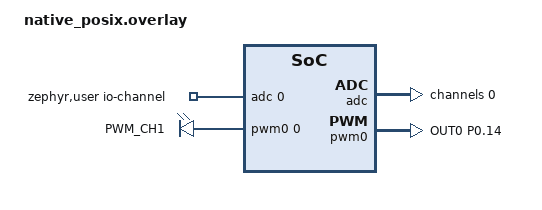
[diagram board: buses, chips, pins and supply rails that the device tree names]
/ {
        zephyr,user {
            io-channels = <&adc 0>;
        };
        aliases {
        // add your aliases here; examples:
        heartbeat = &led0;  // this corresponds to LED1 on the board
        blinker = &led1;
        // buzzer = &led2;
        error = &led3;
        readbutton = &button0;  // this corresponds to SW1 on the board
        // samplingbutton = &button1;
        sleepbutton = &button2;
        resetbutton = &button3;
        vadc = &vadc;
        pwm1 = &pwmch1;
        };
        pwm {
            compatible = "pwm-leds";
            pwmch1: pwm_1 {
                pwms = < &pwm0 0 PWM_MSEC(1) PWM_POLARITY_INVERTED>;  // 0 - channel
                label = "PWM_CH1";
            };
        };
};

&adc {
    #address-cells = <1>;
    #size-cells = <0>;

    vadc: channel@0 {
        reg = <0>;  // channel number
        zephyr,reference = "ADC_REF_INTERNAL";  // voltage ref for SA (0.6 V)
        zephyr,gain = "ADC_GAIN_1_5"; // gain factor to scale ref voltage (1/gain)
        zephyr,acquisition-time = <ADC_ACQ_TIME_DEFAULT>;
        zephyr,input-positive = <NRF_SAADC_AIN0>; // P0.02
        zephyr,resolution = <12>;  // bit depth
    };
    status = "okay"; // enable the ADC
};

&pwm0 {
    compatible = "nordic,nrf-pwm";
    reg = <0x4001c000 0x1000>;
    interrupts = <28 NRF_DEFAULT_IRQ_PRIORITY>;
    status = "okay";
    #pwm-cells = <3>;
    pinctrl-0 = <&pwm0_default>;
    pinctrl-names = "default", "sleep";
};

&pinctrl {
    compatible = "nordic,nrf-pinctrl";
    status = "okay";
    pwm0_default: pwm0_default {
        group1 {
            psels = <NRF_PSEL(PWM_OUT0, 0, 14)>; // P0.14, channel 0
            nordic,invert;
        };
    };
};
